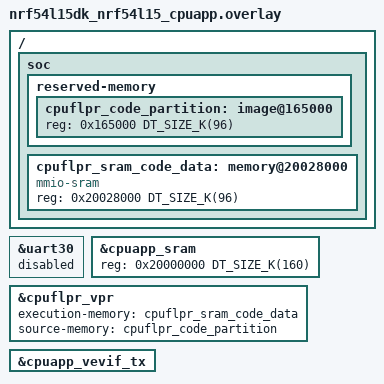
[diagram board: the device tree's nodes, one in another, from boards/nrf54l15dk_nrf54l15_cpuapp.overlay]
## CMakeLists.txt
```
#
# Copyright (c) 2020 Nordic Semiconductor ASA
#
# SPDX-License-Identifier: LicenseRef-Nordic-5-Clause
#
cmake_minimum_required(VERSION 3.20.0)

find_package(Zephyr REQUIRED HINTS $ENV{ZEPHYR_BASE})
project(sabrina-cts)

FILE(GLOB app_sources src/*.c)
# NORDIC SDK APP START
target_sources(app PRIVATE ${app_sources})
# NORDIC SDK APP END
```

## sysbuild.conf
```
# Add MCUboot
SB_CONFIG_BOOTLOADER_MCUBOOT=y

# Enable dual slots in application mode for DFU  
SB_CONFIG_MCUBOOT_MODE_SINGLE_APP=n

# Add private key for MCUboot
SB_CONFIG_BOOT_SIGNATURE_KEY_FILE="\${APP_DIR}/private_key.pem"

# Configure key type
SB_CONFIG_MCUBOOT_SIGNATURE_USING_KMU=y
SB_CONFIG_BOOT_SIGNATURE_TYPE_ED25519=y
```

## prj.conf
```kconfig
#
# Copyright (c) 2020 Nordic Semiconductor ASA
#
# SPDX-License-Identifier: LicenseRef-Nordic-5-Clause
#

CONFIG_HEAP_MEM_POOL_SIZE=1024
CONFIG_SYSTEM_WORKQUEUE_STACK_SIZE=2048

CONFIG_BT=y
CONFIG_BT_PERIPHERAL=y
CONFIG_BT_DEVICE_NAME="Sabrina-MMD"
CONFIG_BT_SMP=y
CONFIG_BT_GATT_CLIENT=y
CONFIG_BT_GATT_DM=y

# Enable CTS client
CONFIG_BT_CTS_CLIENT=y

# Enable bonding
CONFIG_BT_SETTINGS=y
CONFIG_FLASH_PAGE_LAYOUT=y

# Enable DK LED and Buttons library
CONFIG_DK_LIBRARY=y

# Enable logging
CONFIG_LOG=y

# Enable mcumgr DFU in application
# Enable MCUMGR 
CONFIG_MCUMGR=y  # Enable MCUMGR management for both OS and Images
CONFIG_MCUMGR_GRP_OS=y
CONFIG_MCUMGR_GRP_IMG=y  # Configure MCUMGR transport to UART
CONFIG_MCUMGR_TRANSPORT_UART=y  # Dependencies

# Configure dependencies for CONFIG_MCUMGR 
CONFIG_NET_BUF=y
CONFIG_ZCBOR=y
CONFIG_CRC=y  # Configure dependencies for CONFIG_MCUMGR_GRP_IMG 
CONFIG_FLASH=y
CONFIG_IMG_MANAGER=y  # Configure dependencies for CONFIG_IMG_MANAGER 
CONFIG_STREAM_FLASH=y
CONFIG_FLASH_MAP=y  # Configure dependencies for CONFIG_MCUMGR_TRANSPORT_UART 
CONFIG_BASE64=y
```

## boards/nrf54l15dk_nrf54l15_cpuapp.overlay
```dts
// STEP 3.2 - Add overlay to enable FLPR core 
/ {
 soc {
    reserved-memory {
        #address-cells = <1>;
        #size-cells = <1>;
        cpuflpr_code_partition: image@165000 {
        /* FLPR core code partition */
        reg = <0x165000 DT_SIZE_K(96)>;
        };
    };  
    
    cpuflpr_sram_code_data: memory@20028000 {
        compatible = "mmio-sram";
        reg = <0x20028000 DT_SIZE_K(96)>;
        #address-cells = <1>;
        #size-cells = <1>;
        ranges = <0x0 0x20028000 0x18000>;
        };
    };
};  

&uart30 {
    status = "reserved";
};  

&cpuapp_sram {
    reg = <0x20000000 DT_SIZE_K(160)>;
    ranges = <0x0 0x20000000 0x28000>;
    };  
    
&cpuflpr_vpr {
    status = "okay";
    execution-memory = <&cpuflpr_sram_code_data>;
    source-memory = <&cpuflpr_code_partition>;
    };

&cpuapp_vevif_tx {
    status = "okay";
};
```

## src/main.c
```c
/*
 * Copyright (c) 2020 Nordic Semiconductor ASA
 *
 * SPDX-License-Identifier: LicenseRef-Nordic-5-Clause
 */

#include <zephyr/kernel.h>
//#include <zephyr/sys/LOG_INF.h>
#include <zephyr/sys/byteorder.h>

#include <zephyr/bluetooth/bluetooth.h>
#include <zephyr/bluetooth/conn.h>
#include <zephyr/bluetooth/uuid.h>
#include <zephyr/bluetooth/gatt.h>
#include <zephyr/bluetooth/hci.h>
#include <bluetooth/gatt_dm.h>
#include <bluetooth/services/cts_client.h>

#include <zephyr/settings/settings.h>
#include <zephyr/logging/log.h>
#include <dk_buttons_and_leds.h>

#define DEVICE_NAME CONFIG_BT_DEVICE_NAME
#define DEVICE_NAME_LEN (sizeof(DEVICE_NAME) - 1)

#define RUN_STATUS_LED DK_LED1
#define CON_STATUS_LED DK_LED2
#define RUN_LED_BLINK_INTERVAL 1000

#define KEY_READ_TIME DK_BTN1_MSK

LOG_MODULE_REGISTER(Sabrina_Main,LOG_LEVEL_DBG);

static struct bt_cts_client cts_c;
static struct k_work adv_work;
static bool has_cts;

static const struct bt_data ad[] = {
	BT_DATA_BYTES(BT_DATA_GAP_APPEARANCE,
		      (CONFIG_BT_DEVICE_APPEARANCE >> 0) & 0xff,
		      (CONFIG_BT_DEVICE_APPEARANCE >> 8) & 0xff),
	BT_DATA_BYTES(BT_DATA_FLAGS, (BT_LE_AD_LIMITED | BT_LE_AD_NO_BREDR)),
	BT_DATA_BYTES(BT_DATA_SOLICIT16, BT_UUID_16_ENCODE(BT_UUID_CTS_VAL)),
	BT_DATA(BT_DATA_NAME_COMPLETE, DEVICE_NAME, DEVICE_NAME_LEN),
};

static const char *day_of_week[] = { "Unknown",	  "Monday",   "Tuesday",
				     "Wednesday", "Thursday", "Friday",
				     "Saturday",  "Sunday" };

static const char *month_of_year[] = { "Unknown",   "January", "February",
				       "March",	    "April",   "May",
				       "June",	    "July",    "August",
				       "September", "October", "November",
				       "December" };

static void current_time_print(struct bt_cts_current_time *current_time)
{
	LOG_INF("\nCurrent Time:\n");
	LOG_INF("\nDate:\n");

	LOG_INF("\tDay of week   %s\n",
	       day_of_week[current_time->exact_time_256.day_of_week]);

	if (current_time->exact_time_256.day == 0) {
		LOG_INF("\tDay of month  Unknown\n");
	} else {
		LOG_INF("\tDay of month  %u\n",
		       current_time->exact_time_256.day);
	}

	LOG_INF("\tMonth of year %s\n",
	       month_of_year[current_time->exact_time_256.month]);
	if (current_time->exact_time_256.year == 0) {
		LOG_INF("\tYear          Unknown\n");
	} else {
		LOG_INF("\tYear          %u\n",
		       current_time->exact_time_256.year);
	}
	LOG_INF("\nTime:\n");
	LOG_INF("\tHours     %u\n", current_time->exact_time_256.hours);
	LOG_INF("\tMinutes   %u\n", current_time->exact_time_256.minutes);
	LOG_INF("\tSeconds   %u\n", current_time->exact_time_256.seconds);
	LOG_INF("\tFractions %u/256 of a second\n",
	       current_time->exact_time_256.fractions256);

	LOG_INF("\nAdjust reason:\n");
	LOG_INF("\tDaylight savings %x\n",
	       current_time->adjust_reason.change_of_daylight_savings_time);
	LOG_INF("\tTime zone        %x\n",
	       current_time->adjust_reason.change_of_time_zone);
	LOG_INF("\tExternal update  %x\n",
	       current_time->adjust_reason.external_reference_time_update);
	LOG_INF("\tManual update    %x\n",
	       current_time->adjust_reason.manual_time_update);
}

static void notify_current_time_cb(struct bt_cts_client *cts_c,
				   struct bt_cts_current_time *current_time)
{
	current_time_print(current_time);
}

static void enable_notifications(void)
{
	int err;

	if (has_cts && (bt_conn_get_security(cts_c.conn) >= BT_SECURITY_L2)) {
		err = bt_cts_subscribe_current_time(&cts_c,
						    notify_current_time_cb);
		if (err) {
			LOG_ERR("Cannot subscribe to current time value notification (err %d)\n",
			       err);
		}
	}
}

static void discover_completed_cb(struct bt_gatt_dm *dm, void *ctx)
{
	int err;

	LOG_INF("The discovery procedure succeeded\n");

	bt_gatt_dm_data_print(dm);

	err = bt_cts_handles_assign(dm, &cts_c);
	if (err) {
		LOG_ERR("Could not assign CTS client handles, error: %d\n", err);
	} else {
		has_cts = true;

		if (bt_conn_get_security(cts_c.conn) < BT_SECURITY_L2) {
			err = bt_conn_set_security(cts_c.conn, BT_SECURITY_L2);
			if (err) {
				LOG_ERR("Failed to set security (err %d)\n",
				       err);
			}
		} else {
			enable_notifications();
		}
	}

	err = bt_gatt_dm_data_release(dm);
	if (err) {
		LOG_ERR("Could not release the discovery data, error "
		       "code: %d\n",
		       err);
	}
}

static void discover_service_not_found_cb(struct bt_conn *conn, void *ctx)
{
	LOG_INF("The service could not be found during the discovery\n");
}

static void discover_error_found_cb(struct bt_conn *conn, int err, void *ctx)
{
	LOG_INF("The discovery procedure failed, err %d\n", err);
}

static const struct bt_gatt_dm_cb discover_cb = {
	.completed = discover_completed_cb,
	.service_not_found = discover_service_not_found_cb,
	.error_found = discover_error_found_cb,
};


static void adv_work_handler(struct k_work *work)
{
	int err = bt_le_adv_start(BT_LE_ADV_CONN_FAST_2, ad, ARRAY_SIZE(ad), NULL, 0);

	if (err) {
		LOG_ERR("Advertising failed to start (err %d)\n", err);
		return;
	}

	LOG_INF("Advertising successfully started\n");
}

static void advertising_start(void)
{
	k_work_submit(&adv_work);
}

static void connected(struct bt_conn *conn, uint8_t err)
{
	char addr[BT_ADDR_LE_STR_LEN];

	if (err) {
		LOG_ERR("Connection failed, err 0x%02x %s\n", err, bt_hci_err_to_str(err));
		return;
	}

	bt_addr_le_to_str(bt_conn_get_dst(conn), addr, sizeof(addr));
	LOG_INF("Connected %s\n", addr);

	dk_set_led_on(CON_STATUS_LED);

	has_cts = false;

	err = bt_gatt_dm_start(conn, BT_UUID_CTS, &discover_cb, NULL);
	if (err) {
		LOG_ERR("Failed to start discovery (err %d)\n", err);
	}
}

static void disconnected(struct bt_conn *conn, uint8_t reason)
{
	char addr[BT_ADDR_LE_STR_LEN];

	bt_addr_le_to_str(bt_conn_get_dst(conn), addr, sizeof(addr));
	LOG_INF("Disconnected from %s, reason 0x%02x %s\n", addr, reason, bt_hci_err_to_str(reason));

	dk_set_led_off(CON_STATUS_LED);
}

static void security_changed(struct bt_conn *conn, bt_security_t level,
			     enum bt_security_err err)
{
	char addr[BT_ADDR_LE_STR_LEN];

	bt_addr_le_to_str(bt_conn_get_dst(conn), addr, sizeof(addr));

	if (!err) {
		LOG_INF("Security changed: %s level %u\n", addr, level);

		enable_notifications();
	} else {
		LOG_INF("Security failed: %s level %u err %d %s\n", addr, level, err,
		       bt_security_err_to_str(err));
	}
}

static void recycled_cb(void)
{
	LOG_INF("Connection object available from previous conn. Disconnect is complete!\n");
	advertising_start();
}

BT_CONN_CB_DEFINE(conn_callbacks) = {
	.connected        = connected,
	.disconnected     = disconnected,
	.security_changed = security_changed,
	.recycled         = recycled_cb,
};

static void auth_cancel(struct bt_conn *conn)
{
	char addr[BT_ADDR_LE_STR_LEN];

	bt_addr_le_to_str(bt_conn_get_dst(conn), addr, sizeof(addr));

	LOG_INF("Pairing cancelled: %s\n", addr);

	bt_conn_disconnect(conn, BT_HCI_ERR_REMOTE_USER_TERM_CONN);
}

static void pairing_complete(struct bt_conn *conn, bool bonded)
{
	char addr[BT_ADDR_LE_STR_LEN];

	bt_addr_le_to_str(bt_conn_get_dst(conn), addr, sizeof(addr));

	LOG_INF("Pairing completed: %s, bonded: %d\n", addr, bonded);
}

static void pairing_failed(struct bt_conn *conn, enum bt_security_err reason)
{
	char addr[BT_ADDR_LE_STR_LEN];

	bt_addr_le_to_str(bt_conn_get_dst(conn), addr, sizeof(addr));

	LOG_INF("Pairing failed conn: %s, reason %d %s\n", addr, reason,
	       bt_security_err_to_str(reason));

	bt_conn_disconnect(conn, BT_HCI_ERR_REMOTE_USER_TERM_CONN);
}

static struct bt_conn_auth_cb conn_auth_callbacks = {
	.cancel = auth_cancel,
};

static struct bt_conn_auth_info_cb conn_auth_info_callbacks = {
	.pairing_complete = pairing_complete,
	.pairing_failed = pairing_failed
};

static void read_current_time_cb(struct bt_cts_client *cts_c,
				 struct bt_cts_current_time *current_time,
				 int err)
{
	char addr[BT_ADDR_LE_STR_LEN];

	bt_addr_le_to_str(bt_conn_get_dst(cts_c->conn), addr, sizeof(addr));

	if (err) {
		LOG_ERR("Cannot read Current Time: %s, error: %d\n", addr, err);
		return;
	}

	current_time_print(current_time);
}

static void button_changed(uint32_t button_state, uint32_t has_changed)
{
	uint32_t buttons = button_state & has_changed;
	int err;

	if (buttons & KEY_READ_TIME) {
		err = bt_cts_read_current_time(&cts_c, read_current_time_cb);
		if (err) {
			LOG_ERR("Failed reading current time (err: %d)\n", err);
		}
	}
}

static int init_button(void)
{
	int err;

	err = dk_buttons_init(button_changed);
	if (err) {
		LOG_ERR("Cannot init buttons (err: %d)\n", err);
	}

	return err;
}

int main(void)
{
	int blink_status = 0;
	int err;

	LOG_INF("Starting Sabrina - MMD\n");

	err = bt_cts_client_init(&cts_c);
	if (err) {
		LOG_ERR("CTS client init failed (err %d)\n", err);
		return 0;
	}

	err = dk_leds_init();
	if (err) {
		LOG_ERR("LEDs init failed (err %d)\n", err);
		return 0;
	}

	err = init_button();
	if (err) {
		LOG_ERR("Button init failed (err %d)\n", err);
		return 0;
	}

	err = bt_enable(NULL);
	if (err) {
		LOG_ERR("BLE init failed (err %d)\n", err);
		return 0;
	}

	if (IS_ENABLED(CONFIG_SETTINGS)) {
		settings_load();
	}

	err = bt_conn_auth_cb_register(&conn_auth_callbacks);
	if (err) {
		LOG_ERR("Failed to register authorization callbacks\n");
		return 0;
	}

	err = bt_conn_auth_info_cb_register(&conn_auth_info_callbacks);
	if (err) {
		LOG_ERR("Failed to register authorization info callbacks.\n");
		return 0;
	}

	k_work_init(&adv_work, adv_work_handler);
	advertising_start();

	for (;;) {
		dk_set_led(RUN_STATUS_LED, (++blink_status) % 2);
		k_sleep(K_MSEC(RUN_LED_BLINK_INTERVAL));
	}
}
```
